# CY8C5888AXI_LP096 register map
File version: 0.1
Registers are 8-bit, read-write, no defined reset value unless marked. A register's access mark holds for its fields unless they carry their own. Offsets are from the block's base; [hi:lo] are bit positions; {n}, {i} and the like mark numbered series; 'fields as' and 'values as' point back to an identical list.

## ADC_SAR_2 — SAR ADC
Base 0x00000000
0x40004616 SAR_TR0 — SAR trim register
{0x40005908+i} SAR_CSR{i} (i=0..6) — SAR status and control register {i}
0x40005B28 SAR_SW0 — SAR Analog Routing Register 0
{0x40005B28+i} SAR_SW{i} (i=2..4) — SAR Analog Routing Register {i}
0x40005B2E SAR_SW6 — SAR Analog Routing Register 6
0x40005B2F SAR_CLK — SAR Clock Selection Register
0x40005BA2 SAR_WRK 16-bit — SAR working register

## Opamp_1
Base 0x00000000
0x400043A4 PM_ACT_CFG4 — Active Power Mode Configuration Register 4
  [3:0] EN_OPAMP — Enables subsystems during active power mode
    0=Blk_0 (Enables analog linear output buffer for Opamp block 0); 2=Blk_1 (Enables analog linear output buffer for Opamp block 1); 4=Blk_2 (Enables analog linear output buffer for Opamp block 2); 8=Blk_3 (Enables analog linear output buffer for Opamp block 3)
0x400043B4 PM_STBY_CFG4 — Standby Power Mode Configuration Register 4
  [3:0] EN_OPAMP — Enables subsystems during standby power mode
    values as PM_ACT_CFG4.EN_OPAMP
0x40004622 OPAMP__TR0 — Analog Output Buffer Trim Register 0
  [4:0] offset_trim — Offset Trim: 420uV typical step size; +/- 6.8mV offset trimmable range
0x40004623 OPAMP__TR1 — Analog Output Buffer Trim Register 1
0x4000585A OPAMP__CR — Analog Output Buffer Configuration Register
  [1:0] pwr_mode — Power Mode
    0=Default_Fast (Default Power mode Fast); 1=Slow (Power Mode Slow); 2=Medium (Power Mode Medium); 3=Fast (Power Mode Fast)
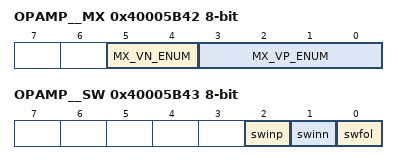
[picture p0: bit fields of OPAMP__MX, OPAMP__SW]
0x40005B42 OPAMP__MX — Analog Buffer Input Selection Register
  [5:4] MX_VN_ENUM — MUX select VN (Negative terminal input)
    0=OPAMP0_MX_VN_DEFAULT (Default - Not Connected (NC)); 1=OPAMP0_MX_VN_AG4 (MUX Selection AGL(4)); 2=OPAMP0_MX_VN_AG6 (MUX Selection AGL(6)); 3=OPAMP0_MX_VN_0x3 (Reserved (NC))
  [3:0] MX_VP_ENUM — MUX select VP (Positive terminal input)
    0=OPAMP0_MX_VP_DEFAULT (Default - Not Connected (NC)); {v}=OPAMP0_MX_VP_AG{v+3} (MUX Selection AGL({v+3})) (v=1..4); {v}=OPAMP0_MX_VP_ABUS{v-5} (MUX Selection ABUSL({v-5})) (v=5..8); 9=OPAMP0_MX_VP_VREF (MUX Selection: OPAMP Voltage Reference); {v}=OPAMP0_MX_VP_H_{0x0+v} (Reserved (NC)) (v=10..15)
0x40005B43 OPAMP__SW — Analog Buffer Routing Switch Register
  [2] swinp — Switch Enable Positive Input
  [1] swinn — Switch Enable Negative Input
  [0] swfol — Switch Enable Follow

## QuadDec_1
Base 0x00000000
0x40006404 QuadDec_1_Cnt16_COUNTER 16-bit — Counter value
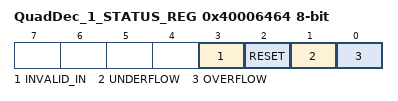
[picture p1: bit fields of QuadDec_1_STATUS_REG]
0x40006464 QuadDec_1_STATUS_REG — Quadrature Decoder Status Register
  [3] INVALID_IN ro — Invalid state transition on the A and B inputs
  [2] RESET ro — Counter Reset due index
  [1] UNDERFLOW ro — Counter underflow
  [0] OVERFLOW ro — Counter overflow

## QuadDec_1_Cnt16
Base 0x00000000
0x40006404 QuadDec_1_Cnt16_COUNTER 16-bit — UDB.A0 - Current Counter Value
0x40006424 QuadDec_1_Cnt16_PERIOD 16-bit — UDB.D0 - Assigned Period
0x40006434 QuadDec_1_Cnt16_COMPARE 16-bit — UDB.D1 - Assigned Compare Value
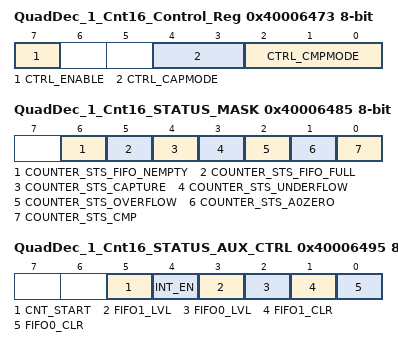
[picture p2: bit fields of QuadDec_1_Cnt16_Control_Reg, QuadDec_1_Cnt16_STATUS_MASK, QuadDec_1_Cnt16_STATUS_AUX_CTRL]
0x40006473 QuadDec_1_Cnt16_Control_Reg — UDB Control Register - Assigned Control Register Value
  [7] CTRL_ENABLE — Enable Counter
  [4:3] CTRL_CAPMODE — Capture mode
  [2:0] CTRL_CMPMODE — Compare mode
0x40006485 QuadDec_1_Cnt16_STATUS_MASK — UDB Status bits Interrupt Mask Enable Register
  [6] COUNTER_STS_FIFO_NEMPTY — FIFO Not Empty Status
  [5] COUNTER_STS_FIFO_FULL — FIFO Full Status
  [4] COUNTER_STS_CAPTURE — Capture Status
  [3] COUNTER_STS_UNDERFLOW — Underflow status
  [2] COUNTER_STS_OVERFLOW — Overflow status
  [1] COUNTER_STS_A0ZERO — A0 Zero ouput status
  [0] COUNTER_STS_CMP — Compare output status
0x40006495 QuadDec_1_Cnt16_STATUS_AUX_CTRL — UDB Auxilliary Control Register
  [5] CNT_START — FIFO0 clear
    0=E_CNT_START0 (Disable counter); 1=E_CNT_START1 (Enable counter)
  [4] INT_EN
    0=E_INT_EN0 (Interrupt disabled); 1=E_INT_EN1 (Interrupt enabled)
  [3] FIFO1_LVL — FIFO level
    0=E_FIFO_LVL_0 (FIFO LVL: input mode: FIFO not full; output mode: FIFO not empty); 1=E_FIFO_LVL_1 (FIFO LVL: input mode: FIFO at least 1/2 empty; output mode: FIFO at least 1/2 full)
  [2] FIFO0_LVL — FIFO level
    values as FIFO1_LVL
  [1] FIFO1_CLR — FIFO1 clear
    0=E_FIFO_CLR_0 (Normal FIFO operation); 1=E_FIFO_CLR_1 (Clear FIFO state)
  [0] FIFO0_CLR — FIFO0 clear
    values as FIFO1_CLR

## USBUART_1 — USBFS
Base 0x00000000
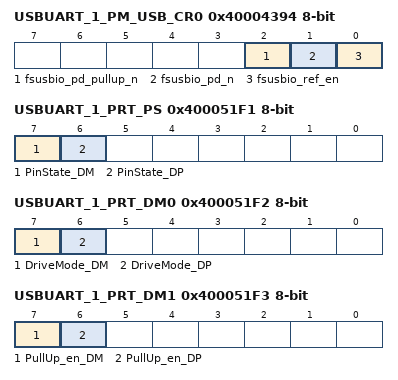
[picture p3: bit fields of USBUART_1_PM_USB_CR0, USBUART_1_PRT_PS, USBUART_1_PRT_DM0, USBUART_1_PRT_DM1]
0x40004394 USBUART_1_PM_USB_CR0 — USB Power Mode Control Register 0
  [2] fsusbio_pd_pullup_n, [1] fsusbio_pd_n, [0] fsusbio_ref_en
0x400043A5 USBUART_1_PM_ACT_CFG — Active Power Mode Configuration Register
0x400043B5 USBUART_1_PM_STBY_CFG — Standby Power Mode Configuration Register
0x400051F1 USBUART_1_PRT_PS — Port Pin State Register
  [7] PinState_DM ro, [6] PinState_DP ro
0x400051F2 USBUART_1_PRT_DM0 — Port Drive Mode Register
  [7] DriveMode_DM, [6] DriveMode_DP
0x400051F3 USBUART_1_PRT_DM1 — Port Drive Mode Register
  [7] PullUp_en_DM, [6] PullUp_en_DP
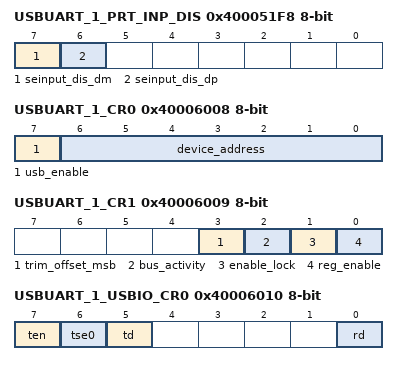
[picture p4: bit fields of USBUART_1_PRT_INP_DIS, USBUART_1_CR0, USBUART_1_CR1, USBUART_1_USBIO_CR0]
0x400051F8 USBUART_1_PRT_INP_DIS — Input buffer disable override
  [7] seinput_dis_dm, [6] seinput_dis_dp
0x40006000 USBUART_1_EP0_DR0 — bmRequestType
0x40006001 USBUART_1_EP0_DR1 — bRequest
0x40006002 USBUART_1_EP0_DR2 — wValueLo
0x40006003 USBUART_1_EP0_DR3 — wValueHi
0x40006004 USBUART_1_EP0_DR4 — wIndexLo
0x40006005 USBUART_1_EP0_DR5 — wIndexHi
0x40006006 USBUART_1_EP0_DR6 — lengthLo
0x40006007 USBUART_1_EP0_DR7 — lengthHi
0x40006008 USBUART_1_CR0 — USB Control Register 0
  [7] usb_enable, [6:0] device_address ro
0x40006009 USBUART_1_CR1 — USB Control Register 1
  [3] trim_offset_msb, [2] bus_activity, [1] enable_lock, [0] reg_enable
{0x40005FFE+0x10*i} USBUART_1_SIE_EP{i}_CR0 (i=1..8) — The Endpoint{i} Control Register
0x40006010 USBUART_1_USBIO_CR0 — USBIO Control Register 0
  [7] ten, [6] tse0, [5] td, [0] rd ro
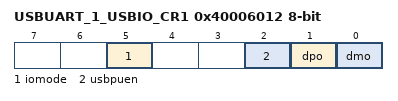
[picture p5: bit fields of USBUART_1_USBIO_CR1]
0x40006012 USBUART_1_USBIO_CR1 — USBIO Control Register 1
  [5] iomode, [2] usbpuen, [1] dpo ro, [0] dmo ro
0x4000608C USBUART_1_BUF_SIZE — Dedicated Endpoint Buffer Size Register
0x4000608E USBUART_1_EP_ACTIVE — Endpoint Active Indication Register
0x4000608F USBUART_1_EP_TYPE — Endpoint Type (IN/OUT) Indication
0x4000609D USBUART_1_USB_CLK_EN — USB Block Clock Enable Register
